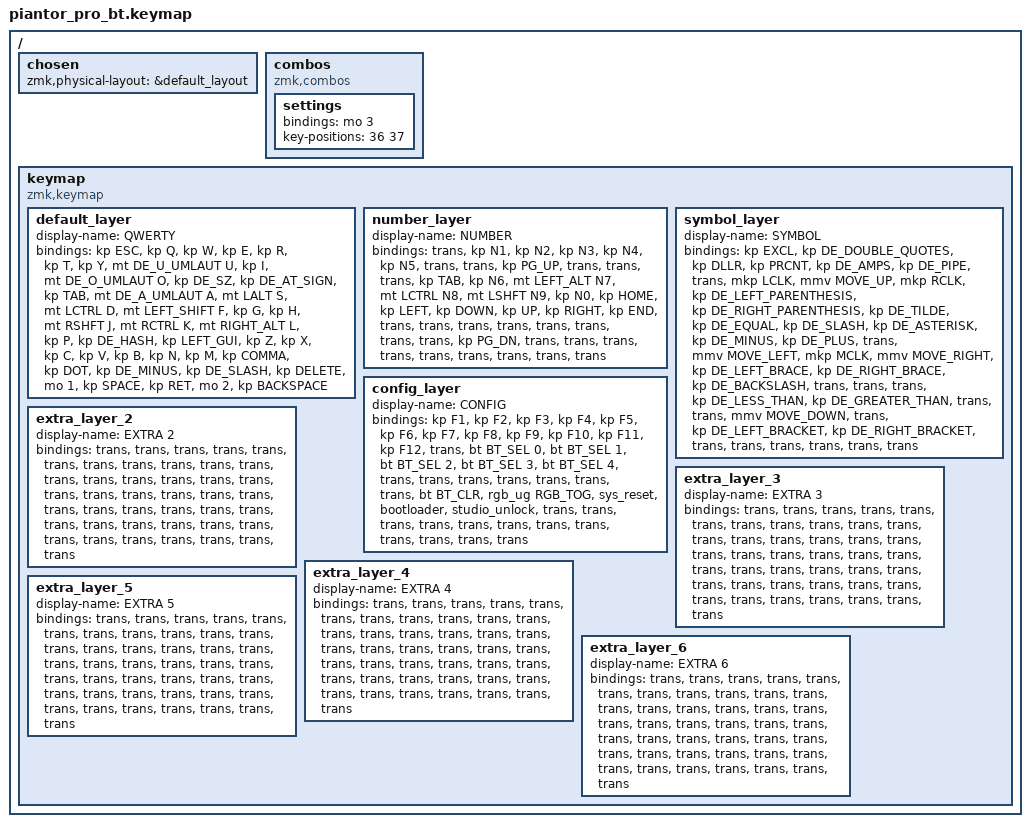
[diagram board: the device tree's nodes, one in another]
/*
 * Copyright (c) 2020 The ZMK Contributors
 *
 * SPDX-License-Identifier: MIT
 */

#include <behaviors.dtsi>
#include <dt-bindings/zmk/bt.h>
#include <dt-bindings/zmk/keys.h>
#include <dt-bindings/zmk/pointing.h>
#include <dt-bindings/zmk/rgb.h>
#include "keys_de.h"

/ {
    chosen { zmk,physical-layout = &default_layout; };
};

/ {
    combos {
        compatible = "zmk,combos";

        settings {
            bindings = <&mo 3>;
            key-positions = <36 37>;
        };
    };

    keymap {
        compatible = "zmk,keymap";

        default_layer {
            display-name = "QWERTY";

            // --------------------------------------------------------------------------------
            // |  TAB |  Q  |  W  |  E  |  R  |  T  |  Y  |  U   |  I  |  O  |  P  | BSPC |
            // | CTRL |  A  |  S  |  D  |  F  |  G  |  H  |  J   |  K  |  L  |  ;  |  '   |
            // | SHFT |  Z  |  X  |  C  |  V  |  B  |  N  |  M   |  ,  |  .  |  /  | ESC  |
            //                    | GUI | LWR | SPC | ENT | RSE  | ALT |

            bindings = <
&kp ESC  &kp Q  &kp W  &kp E  &kp R  &kp T  &kp Y  &mt DE_U_UMLAUT U  &kp I  &mt DE_O_UMLAUT O  &kp DE_SZ  &kp DE_AT_SIGN  &kp TAB  &mt DE_A_UMLAUT A  &mt LALT S  &mt LCTRL D  &mt LEFT_SHIFT F  &kp G  &kp H  &mt RSHFT J  &mt RCTRL K  &mt RIGHT_ALT L  &kp P  &kp DE_HASH  &kp LEFT_GUI  &kp Z  &kp X  &kp C  &kp V  &kp B  &kp N  &kp M  &kp COMMA  &kp DOT  &kp DE_MINUS  &kp DE_SLASH  &kp DELETE  &mo 1  &kp SPACE  &kp RET  &mo 2  &kp BACKSPACE
            >;
        };

        number_layer {
            display-name = "NUMBER";

            // -----------------------------------------------------------------------------------------
            // |  TAB |  1  |  2  |  3  |  4  |  5    |  6  |  7  |  8  |  9  |  0  | BSPC |
            // | CTRL | BT1 | BT2 | BT3 | BT4 | BT5   | LFT | DWN |  UP | RGT |     |      |
            // | SHFT | BTCR| RGB | RST | BOOT| Unlock|     |     |     |     |     |      |
            //                    | GUI |     | SPC   | ENT |     | ALT |

            bindings = <
&trans  &kp N1  &kp N2  &kp N3  &kp N4  &kp N5  &trans  &trans  &kp PG_UP  &trans  &trans  &trans  &kp TAB  &kp N6  &mt LEFT_ALT N7  &mt LCTRL N8  &mt LSHFT N9  &kp N0  &kp HOME  &kp LEFT  &kp DOWN  &kp UP  &kp RIGHT  &kp END  &trans  &trans  &trans  &trans  &trans  &trans  &trans  &trans  &kp PG_DN  &trans  &trans  &trans  &trans  &trans  &trans  &trans  &trans  &trans
            >;
        };

        symbol_layer {
            display-name = "SYMBOL";

            // -----------------------------------------------------------------------------------------
            // |  TAB |  !  |  @  |  #  |  $  |  %  |  ^  |  &  |  *  |  (  |  )  | BSPC |
            // | CTRL |     |     |     |     |     |  -  |  =  |  [  |  ]  |  \  |  `   |
            // | SHFT |     |     |     |     |     |  _  |  +  |  {  |  }  | "|" |  ~   |
            //                    | GUI |     | SPC | ENT |     | ALT |

            bindings = <
&kp EXCL  &kp DE_DOUBLE_QUOTES  &kp DLLR  &kp PRCNT  &kp DE_AMPS  &kp DE_PIPE  &trans  &mkp LCLK  &mmv MOVE_UP  &mkp RCLK  &kp DE_LEFT_PARENTHESIS  &kp DE_RIGHT_PARENTHESIS  &kp DE_TILDE  &kp DE_EQUAL  &kp DE_SLASH  &kp DE_ASTERISK  &kp DE_MINUS  &kp DE_PLUS  &trans  &mmv MOVE_LEFT  &mkp MCLK  &mmv MOVE_RIGHT  &kp DE_LEFT_BRACE  &kp DE_RIGHT_BRACE  &kp DE_BACKSLASH  &trans  &trans  &trans  &kp DE_LESS_THAN  &kp DE_GREATER_THAN  &trans  &trans  &mmv MOVE_DOWN  &trans  &kp DE_LEFT_BRACKET  &kp DE_RIGHT_BRACKET  &trans  &trans  &trans  &trans  &trans  &trans
            >;
        };

        config_layer {
            display-name = "CONFIG";
            bindings = <
&kp F1  &kp F2  &kp F3  &kp F4  &kp F5  &kp F6  &kp F7  &kp F8  &kp F9  &kp F10  &kp F11  &kp F12  &trans  &bt BT_SEL 0  &bt BT_SEL 1  &bt BT_SEL 2  &bt BT_SEL 3  &bt BT_SEL 4  &trans  &trans  &trans  &trans  &trans  &trans  &trans  &bt BT_CLR  &rgb_ug RGB_TOG  &sys_reset  &bootloader  &studio_unlock  &trans  &trans  &trans  &trans  &trans  &trans  &trans  &trans  &trans  &trans  &trans  &trans
            >;
        };

        extra_layer_2 {
            display-name = "EXTRA 2";
            bindings = <
&trans  &trans  &trans  &trans  &trans  &trans  &trans  &trans  &trans  &trans  &trans  &trans  &trans  &trans  &trans  &trans  &trans  &trans  &trans  &trans  &trans  &trans  &trans  &trans  &trans  &trans  &trans  &trans  &trans  &trans  &trans  &trans  &trans  &trans  &trans  &trans  &trans  &trans  &trans  &trans  &trans  &trans
            >;
        };

        extra_layer_3 {
            display-name = "EXTRA 3";
            bindings = <
&trans  &trans  &trans  &trans  &trans  &trans  &trans  &trans  &trans  &trans  &trans  &trans  &trans  &trans  &trans  &trans  &trans  &trans  &trans  &trans  &trans  &trans  &trans  &trans  &trans  &trans  &trans  &trans  &trans  &trans  &trans  &trans  &trans  &trans  &trans  &trans  &trans  &trans  &trans  &trans  &trans  &trans
            >;
        };

        extra_layer_4 {
            display-name = "EXTRA 4";
            bindings = <
&trans  &trans  &trans  &trans  &trans  &trans  &trans  &trans  &trans  &trans  &trans  &trans  &trans  &trans  &trans  &trans  &trans  &trans  &trans  &trans  &trans  &trans  &trans  &trans  &trans  &trans  &trans  &trans  &trans  &trans  &trans  &trans  &trans  &trans  &trans  &trans  &trans  &trans  &trans  &trans  &trans  &trans
            >;
        };

        extra_layer_5 {
            display-name = "EXTRA 5";
            bindings = <
&trans  &trans  &trans  &trans  &trans  &trans  &trans  &trans  &trans  &trans  &trans  &trans  &trans  &trans  &trans  &trans  &trans  &trans  &trans  &trans  &trans  &trans  &trans  &trans  &trans  &trans  &trans  &trans  &trans  &trans  &trans  &trans  &trans  &trans  &trans  &trans  &trans  &trans  &trans  &trans  &trans  &trans
            >;
        };

        extra_layer_6 {
            display-name = "EXTRA 6";
            bindings = <
&trans  &trans  &trans  &trans  &trans  &trans  &trans  &trans  &trans  &trans  &trans  &trans  &trans  &trans  &trans  &trans  &trans  &trans  &trans  &trans  &trans  &trans  &trans  &trans  &trans  &trans  &trans  &trans  &trans  &trans  &trans  &trans  &trans  &trans  &trans  &trans  &trans  &trans  &trans  &trans  &trans  &trans
            >;
        };
    };
};
